# A31L21x register map
Vendor: VENDOR ABOV Semiconductor Co., Ltd.; Series: A31L21x; File version: 1.0
CPU: CM0+ r0p1, little endian, no MPU, no FPU, VTOR, 2 interrupt priority bits
Registers are 32-bit, read-write, reset 0x0 unless marked. A register's access mark holds for its fields unless they carry their own. Offsets are from the block's base; [hi:lo] are bit positions; {n}, {i} and the like mark numbered series.

## CRC — Cyclic Redundancy Check and Checksum
Base 0x30001000
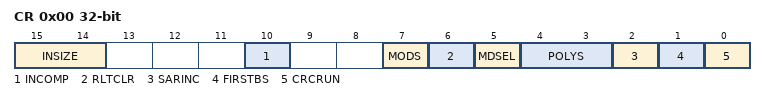
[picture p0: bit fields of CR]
0x00 CR — CRC/Checksum Control Register
  [15:14] INSIZE — Input Data Size Selection
    0=32-bit is the input data size; 1=16-bit is the input data size; 2=8-bit is the input data size
  [10] INCOMP — Input Data Complement
    0=Disable (No effect.); 1=Enable (1's complement of input data)
  [7] MODS — User/Auto Mode Selection
    0=User Mode (Calculate every data written to the CRC_IN register); 1=Auto Mode (Calculate till CRC_SADR == CRC_EADR)
  [6] RLTCLR — CRC/Checksum Result Data Register (CRC_RLT) Initialization
    0=NoEffect; 1=Initialize the CRC_RLT register with the value of CRC_INIT. (This bit is automatically cleared to '0' after operation.)
  [5] MDSEL — CRC/Checksum Selection
    0=CRC (Select CRC.); 1=Checksum (Select Checksum.)
  [4:3] POLYS — Polynomial Selection (CRC only)
    0=CRC16_CCITT (CRC16-CCITT (G1(x) = x16 + x12 + x5 + 1)); 1=CRC16 (CRC16 (G2(x) = x16 + x15 + x2 + 1)); 2=CRC8 (CRC8 (G3(x) = x8 + x2 + x + 1)); 3=CRC32 (CRC32 (G4(x) = x32 + x26 + x23 + x22 + x16 + x12 + x11 + x10 +x8 + x7 + x5 + x4 + x2 + x + 1))
  [2] SARINC — CRC/Checksum Start Address Auto Increment Control (User mode only)
    0=Disable (No effect.); 1=Enable (The CRC/Checksum start address register is incremented as the selected input size every writing to the CRC_IN register.)
  [1] FIRSTBS — First Shifted-in Selection (CRC only)
    0=msbFirst; 1=lsbFirst
  [0] CRCRUN — CRC/Checksum Start/Stop Control
    0=Stop (Not busy. The CRC operation can be finished by writing '0' to this bit while running.); 1=Start CRC operation. This bit is automatically cleared to '0' when the value of CRC_SADR register reaches the value of CRC_EADR register.
0x04 IN — CRC/Checksum Input Data Register
  [31:0] INDATA — CRC Input Data
0x08 RLT ro reset 0xFFFFFFFF — CRC/Checksum Result Data Register
  [31:0] RLTDATA — CRC Result Data
0x0C INIT — CRC/Checksum Initial Data Register
  [31:0] INIDATA — CRC Initial Data
0x10 SADR reset 0x10000000 — CRC/Checksum Start Address Register
  [31:0] SADR — CRC Start Address
0x14 EADR reset 0x1001FFFC — CRC/Checksum End Address Register
  [31:0] EADR — CRC End Address

## LCD — LCD Driver
Base 0x40005000
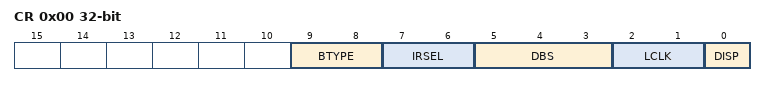
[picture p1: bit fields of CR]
0x00 CR — LCD Driver Control Register
  [9:8] BTYPE — LCD Bias Type Selection
    0=IntRBias (Internal Resistor Bias); 1=ExtRBias (External Resistor Bias); 2=CapBias (Capacitor Bias (Voltage Booster))
  [7:6] IRSEL — Internal LCD Bias Dividing Resistor Selection
    0=RLCD2 (60[kohm]); 1=RLCD1 (30[kohm]); 2=RLCD3 (120[kohm])
  [5:3] DBS — LCD Duty and Bias Selection
    0=8D4B (1/8 duty, 1/4 bias); 1=6D4B (1/6 duty, 1/4 bias); 2=5D3B (1/5 duty, 1/3 bias); 3=4D3B (1/4 duty, 1/3 bias); 4=3D3B (1/3 duty, 1/3 bias); 5=3D2B (1/3 duty, 1/2 bias); 6=2D2B (1/2 duty, 1/2 bias)
  [2:1] LCLK — LCD Clock Selection (When fLCD = 32.768kHz)
    0=128Hz (32.768kHz(fLCD) / 256); 1=256Hz (32.768kHz(fLCD) / 128); 2=512Hz (32.768kHz(fLCD) / 64); 3=1024Hz (32.768kHz(fLCD) / 32)
  [0] DISP — LCD Display Control
    0=Off (Display off); 1=On (Normal display on)
0x04 CCR — LCD Contrast Control Register
  [3:0] VLCD — VLC3 Voltage Control when the capacitor bias is selected by the BTYPE[1:0]
    0=Step0 (VLC3=0.725V (1/3 Bias), VLC3=0.725V (1/2, 1/4 Bias)); 1=Step1 (VLC3=0.750V (1/3 Bias), VLC3=0.750V (1/2, 1/4 Bias)); 2=Step2 (VLC3=0.775V (1/3 Bias), VLC3=0.775V (1/2, 1/4 Bias)); 3=Step3 (VLC3=0.800V (1/3 Bias), VLC3=0.800V (1/2, 1/4 Bias)); 4=Step4 (VLC3=0.825V (1/3 Bias), VLC3=0.825V (1/2, 1/4 Bias)); 5=Step5 (VLC3=0.850V (1/3 Bias), Not available (1/2, 1/4 Bias)); 6=Step6 (VLC3=0.875V (1/3 Bias), Not available (1/2, 1/4 Bias)); 7=Step7 (VLC3=0.900V (1/3 Bias), Not available (1/2, 1/4 Bias)); 8=Step8 (VLC3=0.925V (1/3 Bias), Not available (1/2, 1/4 Bias)); 9=Step9 (VLC3=0.950V (1/3 Bias), Not available (1/2, 1/4 Bias)); 10=Step10 (VLC3=0.975V (1/3 Bias), Not available (1/2, 1/4 Bias)); 11=Step11 (VLC3=1.000V (1/3 Bias), Not available (1/2, 1/4 Bias)); 12=Step12 (VLC3=1.025V (1/3 Bias), Not available (1/2, 1/4 Bias)); 13=Step13 (VLC3=1.050V (1/3 Bias), Not available (1/2, 1/4 Bias)); 14=Step14 (VLC3=1.075V (1/3 Bias), Not available (1/2, 1/4 Bias)); 15=Step15 (VLC3=1.100V (1/3 Bias), Not available (1/2, 1/4 Bias))
{0x10+i} DR{i} 8-bit reset not defined (i=0..44) — LCD Display Data Register {i}
